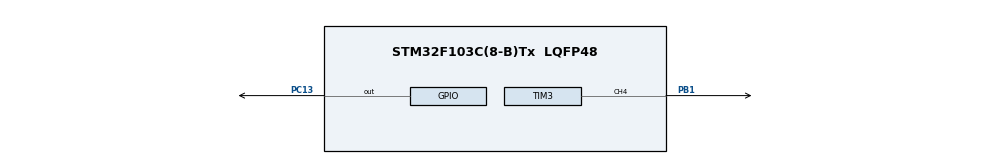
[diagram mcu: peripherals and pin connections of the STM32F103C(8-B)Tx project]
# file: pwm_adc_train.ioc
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Mcu.Family=STM32F1
PD1-OSC_OUT.Mode=HSE-External-Oscillator
TIM3.OCMode_PWM-PWM\ Generation4\ CH4=TIM_OCMODE_PWM2
PC13-TAMPER-RTC.Signal=GPIO_Output
PD0-OSC_IN.Signal=RCC_OSC_IN
TIM3.Channel-PWM\ Generation4\ CH4=TIM_CHANNEL_4
RCC.SYSCLKSource=RCC_SYSCLKSOURCE_HSE
ProjectManager.StackSize=0x400
PD1-OSC_OUT.Signal=RCC_OSC_OUT
PA13.Signal=SYS_JTMS-SWDIO
ProjectManager.TargetToolchain=STM32CubeIDE
TIM3.Period=200
PD0-OSC_IN.Mode=HSE-External-Oscillator
board=custom
NVIC.TIM3_IRQn=true\:0\:0\:false\:false\:true\:true\:true
RCC.APB2Freq_Value=8000000
PA14.Mode=Serial_Wire
TIM3.Prescaler=799
PA13.Mode=Serial_Wire
Mcu.Name=STM32F103C(8-B)Tx
Mcu.Package=LQFP48
PB1.Signal=S_TIM3_CH4
PA14.Signal=SYS_JTCK-SWCLK
ProjectManager.HeapSize=0x200
NVIC.PriorityGroup=NVIC_PRIORITYGROUP_4
RCC.APB1Freq_Value=8000000
VP_TIM3_VS_ClockSourceINT.Mode=Internal
SH.S_TIM3_CH4.0=TIM3_CH4,PWM Generation4 CH4

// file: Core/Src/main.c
/* USER CODE BEGIN Header */
/**
  ******************************************************************************
  * @file           : main.c
  * @brief          : Main program body
  ******************************************************************************
  * @attention
  *
  * <h2><center>&copy; Copyright (c) 2021 STMicroelectronics.
  * All rights reserved.</center></h2>
  *
  * This software component is licensed by ST under BSD 3-Clause license,
  * the "License"; You may not use this file except in compliance with the
  * License. You may obtain a copy of the License at:
  *                        opensource.org/licenses/BSD-3-Clause
  *
  ******************************************************************************
  */
/* USER CODE END Header */
#include "main.h"

TIM_HandleTypeDef htim3;

void SystemClock_Config(void);
static void MX_GPIO_Init(void);
static void MX_TIM3_Init(void);
/* USER CODE BEGIN PFP */
void Set_Angle(int angle);
/* USER CODE END PFP */

int main(void)
{

  /* MCU Configuration--------------------------------------------------------*/

  /* Reset of all peripherals, Initializes the Flash interface and the Systick. */
  HAL_Init();

  /* Configure the system clock */
  SystemClock_Config();

  /* Initialize all configured peripherals */
  MX_GPIO_Init();
  MX_TIM3_Init();
  /* USER CODE BEGIN 2 */

  HAL_TIM_PWM_Start(&htim3, TIM_CHANNEL_4);
  HAL_Delay(10);
  uint16_t dutyCycle = HAL_TIM_ReadCapturedValue(&htim3, TIM_CHANNEL_4);
  /* USER CODE END 2 */

  /* Infinite loop */
  /* USER CODE BEGIN WHILE */

  while (1)
  {

	  Set_Angle(-90);
	  HAL_Delay(500);
	  Set_Angle(-45);
	  HAL_Delay(500);
	  Set_Angle(0);
	  HAL_Delay(500);
	  Set_Angle(45);
	  HAL_Delay(500);
	  Set_Angle(90);
	  HAL_Delay(500);
	  /*for (int i=10; i<20;i++)
	  { TIM3->CCR4 = i;
	  HAL_Delay(1);
	  }
	  for (int i=20; i>10;i--)
	  { TIM3->CCR4 = i;
	  HAL_Delay(1);}
	  TIM3->CCR4 = 0;*/
	/*  while(dutyCycle < __HAL_TIM_GET_AUTORELOAD(&htim3)) {
	//  __HAL_TIM_SET_COMPARE(&htim2, TIM_CHANNEL_1, ++dutyCycle);
	  __HAL_TIM_SET_COMPARE(&htim3, TIM_CHANNEL_4, ++dutyCycle);
	  for (int i=0;i<500;i++);
	  }
	  while(dutyCycle > 0) {
	  //__HAL_TIM_SET_COMPARE(&htim2, TIM_CHANNEL_1, --dutyCycle);
	  __HAL_TIM_SET_COMPARE(&htim3, TIM_CHANNEL_4, --dutyCycle);
	  for (int i=0;i<500;i++);
	  }
	  HAL_GPIO_TogglePin(GPIOC, GPIO_PIN_13);*/

	  //HAL_Delay(400);
    /* USER CODE END WHILE */

  }
}

void SystemClock_Config(void)
{
  RCC_OscInitTypeDef RCC_OscInitStruct = {0};
  RCC_ClkInitTypeDef RCC_ClkInitStruct = {0};

  /** Initializes the RCC Oscillators according to the specified parameters
  * in the RCC_OscInitTypeDef structure.
  */
  RCC_OscInitStruct.OscillatorType = RCC_OSCILLATORTYPE_HSE;
  RCC_OscInitStruct.HSEState = RCC_HSE_ON;
  RCC_OscInitStruct.PLL.PLLState = RCC_PLL_NONE;
  if (HAL_RCC_OscConfig(&RCC_OscInitStruct) != HAL_OK)
  {
    Error_Handler();
  }
  /** Initializes the CPU, AHB and APB buses clocks
  */
  RCC_ClkInitStruct.ClockType = RCC_CLOCKTYPE_HCLK|RCC_CLOCKTYPE_SYSCLK
                              |RCC_CLOCKTYPE_PCLK1|RCC_CLOCKTYPE_PCLK2;
  RCC_ClkInitStruct.SYSCLKSource = RCC_SYSCLKSOURCE_HSE;
  RCC_ClkInitStruct.AHBCLKDivider = RCC_SYSCLK_DIV1;
  RCC_ClkInitStruct.APB1CLKDivider = RCC_HCLK_DIV1;
  RCC_ClkInitStruct.APB2CLKDivider = RCC_HCLK_DIV1;

  if (HAL_RCC_ClockConfig(&RCC_ClkInitStruct, FLASH_LATENCY_0) != HAL_OK)
  {
    Error_Handler();
  }
}

static void MX_TIM3_Init(void)
{

  TIM_ClockConfigTypeDef sClockSourceConfig = {0};
  TIM_MasterConfigTypeDef sMasterConfig = {0};
  TIM_OC_InitTypeDef sConfigOC = {0};

  htim3.Instance = TIM3;
  htim3.Init.Prescaler = 799;
  htim3.Init.CounterMode = TIM_COUNTERMODE_UP;
  htim3.Init.Period = 200;
  htim3.Init.ClockDivision = TIM_CLOCKDIVISION_DIV1;
  htim3.Init.AutoReloadPreload = TIM_AUTORELOAD_PRELOAD_DISABLE;
  if (HAL_TIM_Base_Init(&htim3) != HAL_OK)
  {
    Error_Handler();
  }
  sClockSourceConfig.ClockSource = TIM_CLOCKSOURCE_INTERNAL;
  if (HAL_TIM_ConfigClockSource(&htim3, &sClockSourceConfig) != HAL_OK)
  {
    Error_Handler();
  }
  if (HAL_TIM_PWM_Init(&htim3) != HAL_OK)
  {
    Error_Handler();
  }
  sMasterConfig.MasterOutputTrigger = TIM_TRGO_RESET;
  sMasterConfig.MasterSlaveMode = TIM_MASTERSLAVEMODE_DISABLE;
  if (HAL_TIMEx_MasterConfigSynchronization(&htim3, &sMasterConfig) != HAL_OK)
  {
    Error_Handler();
  }
  sConfigOC.OCMode = TIM_OCMODE_PWM2;
  sConfigOC.Pulse = 0;
  sConfigOC.OCPolarity = TIM_OCPOLARITY_HIGH;
  sConfigOC.OCFastMode = TIM_OCFAST_DISABLE;
  if (HAL_TIM_PWM_ConfigChannel(&htim3, &sConfigOC, TIM_CHANNEL_4) != HAL_OK)
  {
    Error_Handler();
  }
  HAL_TIM_MspPostInit(&htim3);

}

static void MX_GPIO_Init(void)
{
  GPIO_InitTypeDef GPIO_InitStruct = {0};

  /* GPIO Ports Clock Enable */
  __HAL_RCC_GPIOC_CLK_ENABLE();
  __HAL_RCC_GPIOD_CLK_ENABLE();
  __HAL_RCC_GPIOB_CLK_ENABLE();
  __HAL_RCC_GPIOA_CLK_ENABLE();

  /*Configure GPIO pin Output Level */
  HAL_GPIO_WritePin(GPIOC, GPIO_PIN_13, GPIO_PIN_RESET);

  /*Configure GPIO pin : PC13 */
  GPIO_InitStruct.Pin = GPIO_PIN_13;
  GPIO_InitStruct.Mode = GPIO_MODE_OUTPUT_PP;
  GPIO_InitStruct.Pull = GPIO_NOPULL;
  GPIO_InitStruct.Speed = GPIO_SPEED_FREQ_LOW;
  HAL_GPIO_Init(GPIOC, &GPIO_InitStruct);

}

/* USER CODE BEGIN 4 */
void Set_Angle(int angle)
{
	float t;

		t = 1.5 + (float)(angle/90*0.9);
		TIM3->CCR4 = (int)(t*10);

}
/* USER CODE END 4 */

void Error_Handler(void)
{
  __disable_irq();
  while (1)
  {
  }
}

/************************ (C) COPYRIGHT STMicroelectronics *****END OF FILE****/
